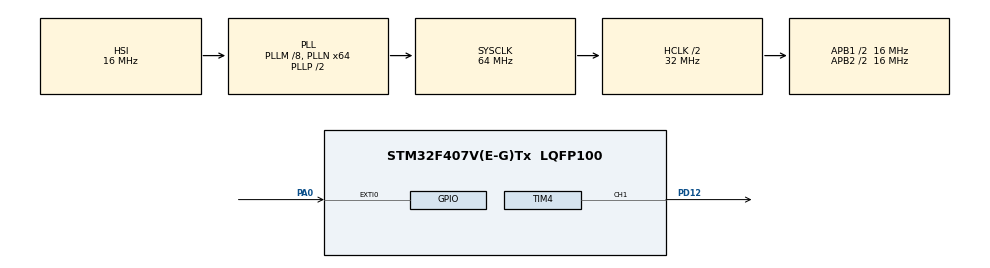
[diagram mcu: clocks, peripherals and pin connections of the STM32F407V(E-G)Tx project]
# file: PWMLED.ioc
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Dma.Request0=TIM4_CH1
Dma.TIM4_CH1.0.Direction=DMA_MEMORY_TO_PERIPH
Dma.TIM4_CH1.0.FIFOMode=DMA_FIFOMODE_DISABLE
Dma.TIM4_CH1.0.Instance=DMA1_Stream0
Dma.TIM4_CH1.0.MemDataAlignment=DMA_MDATAALIGN_HALFWORD
Dma.TIM4_CH1.0.MemInc=DMA_MINC_ENABLE
Dma.TIM4_CH1.0.Mode=DMA_NORMAL
Dma.TIM4_CH1.0.PeriphDataAlignment=DMA_PDATAALIGN_HALFWORD
Dma.TIM4_CH1.0.PeriphInc=DMA_PINC_DISABLE
Dma.TIM4_CH1.0.Priority=DMA_PRIORITY_LOW
Mcu.Family=STM32F4
Mcu.Name=STM32F407V(E-G)Tx
Mcu.Package=LQFP100
NVIC.DMA1_Stream0_IRQn=true\:0\:0\:false\:false\:true\:false\:true
NVIC.EXTI0_IRQn=true\:0\:1\:false\:false\:true\:true\:true
NVIC.PriorityGroup=NVIC_PRIORITYGROUP_0
NVIC.TIM8_UP_TIM13_IRQn=true\:0\:0\:false\:false\:true\:false\:true
NVIC.TimeBase=TIM8_UP_TIM13_IRQn
NVIC.TimeBaseIP=TIM13
PA0-WKUP.GPIO_ModeDefaultEXTI=GPIO_MODE_IT_FALLING
PA0-WKUP.Signal=GPXTI0
PD12.Signal=S_TIM4_CH1
ProjectManager.HeapSize=0x200
ProjectManager.StackSize=0x400
ProjectManager.TargetToolchain=STM32CubeIDE
RCC.48MHZClocksFreq_Value=18285714.285714287
RCC.AHBCLKDivider=RCC_SYSCLK_DIV2
RCC.AHBFreq_Value=32000000
RCC.APB1CLKDivider=RCC_HCLK_DIV2
RCC.APB1Freq_Value=16000000
RCC.APB1TimFreq_Value=32000000
RCC.APB2CLKDivider=RCC_HCLK_DIV2
RCC.APB2Freq_Value=16000000
RCC.APB2TimFreq_Value=32000000
RCC.CortexFreq_Value=32000000
RCC.HCLKFreq_Value=32000000
RCC.HSE_VALUE=8000000
RCC.HSI_VALUE=16000000
RCC.LSE_VALUE=32768
RCC.PLLM=8
RCC.PLLN=64
RCC.PLLQ=7
RCC.SYSCLKFreq_VALUE=64000000
RCC.SYSCLKSource=RCC_SYSCLKSOURCE_PLLCLK
RCC.VCOOutputFreq_Value=128000000
SH.S_TIM4_CH1.0=TIM4_CH1,PWM Generation1 CH1
TIM4.AutoReloadPreload=TIM_AUTORELOAD_PRELOAD_ENABLE
TIM4.Channel-PWM\ Generation1\ CH1=TIM_CHANNEL_1
TIM4.OCMode_PWM-PWM\ Generation1\ CH1=TIM_OCMODE_PWM1
TIM4.Period=1000-1
TIM4.Prescaler=32000-1
TIM4.Pulse-PWM\ Generation1\ CH1=0
VP_SYS_VS_tim13.Mode=TIM13
VP_TIM4_VS_ClockSourceINT.Mode=Internal
board=STM32F407G-DISC1

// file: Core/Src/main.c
/* USER CODE BEGIN Header */
/**
  ******************************************************************************
  * @file           : main.c
  * @brief          : Main program body
  ******************************************************************************
  * @attention
  *
  * <h2><center>&copy; Copyright (c) 2023 STMicroelectronics.
  * All rights reserved.</center></h2>
  *
  * This software component is licensed by ST under BSD 3-Clause license,
  * the "License"; You may not use this file except in compliance with the
  * License. You may obtain a copy of the License at:
  *                        opensource.org/licenses/BSD-3-Clause
  *
  ******************************************************************************
  */
/* USER CODE END Header */
#include "main.h"

TIM_HandleTypeDef htim4;
DMA_HandleTypeDef hdma_tim4_ch1;

/* USER CODE BEGIN PV */
uint32_t pulswidth;
/* USER CODE END PV */

void SystemClock_Config(void);
static void MX_GPIO_Init(void);
static void MX_TIM4_Init(void);
static void MX_DMA_Init(void);
/* USER CODE BEGIN PFP */
uint16_t i = 0;
/* USER CODE END PFP */

/* USER CODE BEGIN 0 */
void HAL_GPIO_EXTI_Callback(uint16_t GPIO_Pin)
{
  /* Prevent unused argument(s) compilation warning */
  UNUSED(GPIO_Pin);
  /* NOTE: This function Should not be modified, when the callback is needed,
           the HAL_GPIO_EXTI_Callback could be implemented in the user file
   */
  if (GPIO_Pin == GPIO_PIN_0) {
	  pulswidth =  pulswidth + 250 ;
	  if ( pulswidth > 1000) {

		  pulswidth = 0 ;

	}
	  TIM4 ->CCR1 =  pulswidth ;
}
}
/* USER CODE END 0 */

int main(void)
{

  /* MCU Configuration--------------------------------------------------------*/

  /* Reset of all peripherals, Initializes the Flash interface and the Systick. */
  HAL_Init();

  /* Configure the system clock */
  SystemClock_Config();

  /* Initialize all configured peripherals */
  MX_GPIO_Init();
  MX_TIM4_Init();
  MX_DMA_Init();
  /* USER CODE BEGIN 2 */
//TIM4 ->CCR1 =  pulswidth ;
HAL_TIM_PWM_Start(&htim4,TIM_CHANNEL_1);
//HAL_TIM_PWM_Start_DMA(&htim4, TIM_CHANNEL_1,(uint32_t*)pulswidth, 1);
  /* USER CODE END 2 */

  /* Infinite loop */
  while (1)
  {

  }
}

void SystemClock_Config(void)
{
  RCC_OscInitTypeDef RCC_OscInitStruct = {0};
  RCC_ClkInitTypeDef RCC_ClkInitStruct = {0};

  /** Configure the main internal regulator output voltage
  */
  __HAL_RCC_PWR_CLK_ENABLE();
  __HAL_PWR_VOLTAGESCALING_CONFIG(PWR_REGULATOR_VOLTAGE_SCALE1);
  /** Initializes the RCC Oscillators according to the specified parameters
  * in the RCC_OscInitTypeDef structure.
  */
  RCC_OscInitStruct.OscillatorType = RCC_OSCILLATORTYPE_HSI;
  RCC_OscInitStruct.HSIState = RCC_HSI_ON;
  RCC_OscInitStruct.HSICalibrationValue = RCC_HSICALIBRATION_DEFAULT;
  RCC_OscInitStruct.PLL.PLLState = RCC_PLL_ON;
  RCC_OscInitStruct.PLL.PLLSource = RCC_PLLSOURCE_HSI;
  RCC_OscInitStruct.PLL.PLLM = 8;
  RCC_OscInitStruct.PLL.PLLN = 64;
  RCC_OscInitStruct.PLL.PLLP = RCC_PLLP_DIV2;
  RCC_OscInitStruct.PLL.PLLQ = 7;
  if (HAL_RCC_OscConfig(&RCC_OscInitStruct) != HAL_OK)
  {
    Error_Handler();
  }
  /** Initializes the CPU, AHB and APB buses clocks
  */
  RCC_ClkInitStruct.ClockType = RCC_CLOCKTYPE_HCLK|RCC_CLOCKTYPE_SYSCLK
                              |RCC_CLOCKTYPE_PCLK1|RCC_CLOCKTYPE_PCLK2;
  RCC_ClkInitStruct.SYSCLKSource = RCC_SYSCLKSOURCE_PLLCLK;
  RCC_ClkInitStruct.AHBCLKDivider = RCC_SYSCLK_DIV2;
  RCC_ClkInitStruct.APB1CLKDivider = RCC_HCLK_DIV2;
  RCC_ClkInitStruct.APB2CLKDivider = RCC_HCLK_DIV2;

  if (HAL_RCC_ClockConfig(&RCC_ClkInitStruct, FLASH_LATENCY_1) != HAL_OK)
  {
    Error_Handler();
  }
}

static void MX_TIM4_Init(void)
{

  TIM_ClockConfigTypeDef sClockSourceConfig = {0};
  TIM_MasterConfigTypeDef sMasterConfig = {0};
  TIM_OC_InitTypeDef sConfigOC = {0};

  htim4.Instance = TIM4;
  htim4.Init.Prescaler = 32000-1;
  htim4.Init.CounterMode = TIM_COUNTERMODE_UP;
  htim4.Init.Period = 1000-1;
  htim4.Init.ClockDivision = TIM_CLOCKDIVISION_DIV1;
  htim4.Init.AutoReloadPreload = TIM_AUTORELOAD_PRELOAD_ENABLE;
  if (HAL_TIM_Base_Init(&htim4) != HAL_OK)
  {
    Error_Handler();
  }
  sClockSourceConfig.ClockSource = TIM_CLOCKSOURCE_INTERNAL;
  if (HAL_TIM_ConfigClockSource(&htim4, &sClockSourceConfig) != HAL_OK)
  {
    Error_Handler();
  }
  if (HAL_TIM_PWM_Init(&htim4) != HAL_OK)
  {
    Error_Handler();
  }
  sMasterConfig.MasterOutputTrigger = TIM_TRGO_RESET;
  sMasterConfig.MasterSlaveMode = TIM_MASTERSLAVEMODE_DISABLE;
  if (HAL_TIMEx_MasterConfigSynchronization(&htim4, &sMasterConfig) != HAL_OK)
  {
    Error_Handler();
  }
  sConfigOC.OCMode = TIM_OCMODE_PWM1;
  sConfigOC.Pulse = 0;
  sConfigOC.OCPolarity = TIM_OCPOLARITY_HIGH;
  sConfigOC.OCFastMode = TIM_OCFAST_DISABLE;
  if (HAL_TIM_PWM_ConfigChannel(&htim4, &sConfigOC, TIM_CHANNEL_1) != HAL_OK)
  {
    Error_Handler();
  }
  HAL_TIM_MspPostInit(&htim4);

}

static void MX_DMA_Init(void)
{

  /* DMA controller clock enable */
  __HAL_RCC_DMA1_CLK_ENABLE();

  /* DMA interrupt init */
  /* DMA1_Stream0_IRQn interrupt configuration */
  HAL_NVIC_SetPriority(DMA1_Stream0_IRQn, 0, 0);
  HAL_NVIC_EnableIRQ(DMA1_Stream0_IRQn);

}

static void MX_GPIO_Init(void)
{
  GPIO_InitTypeDef GPIO_InitStruct = {0};

  /* GPIO Ports Clock Enable */
  __HAL_RCC_GPIOA_CLK_ENABLE();
  __HAL_RCC_GPIOD_CLK_ENABLE();

  /*Configure GPIO pin : PA0 */
  GPIO_InitStruct.Pin = GPIO_PIN_0;
  GPIO_InitStruct.Mode = GPIO_MODE_IT_FALLING;
  GPIO_InitStruct.Pull = GPIO_NOPULL;
  HAL_GPIO_Init(GPIOA, &GPIO_InitStruct);

  /* EXTI interrupt init*/
  HAL_NVIC_SetPriority(EXTI0_IRQn, 0, 1);
  HAL_NVIC_EnableIRQ(EXTI0_IRQn);

}

void HAL_TIM_PeriodElapsedCallback(TIM_HandleTypeDef *htim)
{
  if (htim->Instance == TIM13) {
    HAL_IncTick();
  }
}

void Error_Handler(void)
{
  __disable_irq();
  while (1)
  {
  }
}

/************************ (C) COPYRIGHT STMicroelectronics *****END OF FILE****/
